# LargeDummyDevice register map
File version: 1.0
Registers are 32-bit, read-write, no defined reset value unless marked. A register's access mark holds for its fields unless they carry their own. Offsets are from the block's base; [hi:lo] are bit positions.

## PERIPHERAL_81
Base 0x40050000
0x04 REG_1 — Register 1
  [33:30] FIELD_1, [24] FIELD_19, [26:22] FIELD_5, [25:21] FIELD_7, [24:21] FIELD_18, [18:17] FIELD_13, [19:17] FIELD_20, [16:15] FIELD_14, [15:14] FIELD_2, [15:14] FIELD_6, [18:14] FIELD_11, [15:13] FIELD_8, [15:12] FIELD_16, [12:10] FIELD_21, [12:9] FIELD_3, [11:9] FIELD_17, [10:9] FIELD_22, [9:6] FIELD_10, [8:5] FIELD_4, [2] FIELD_12, [4:2] FIELD_15, [3:1] FIELD_23, [2:0] FIELD_9
0x08 REG_2 — Register 2
  [32:30] FIELD_4, [34:30] FIELD_6, [32:28] FIELD_11, [23] FIELD_3, [26:22] FIELD_20, [21] FIELD_1, [19] FIELD_21, [19:16] FIELD_2, [19:15] FIELD_7, [19:15] FIELD_19, [18:14] FIELD_24, [11:10] FIELD_9, [10:8] FIELD_16, [12:8] FIELD_17, [12:8] FIELD_18, [7] FIELD_22, [6] FIELD_8, [8:5] FIELD_15, [6:4] FIELD_5, [5:3] FIELD_13, [5:1] FIELD_12, [2:1] FIELD_23, [0] FIELD_10, [1:0] FIELD_14
0x0C REG_3 — Register 3
  [32:28] FIELD_1, [28] FIELD_5, [29:26] FIELD_4, [26:23] FIELD_7, [24:20] FIELD_9, [15:14] FIELD_14, [11:10] FIELD_11, [11:10] FIELD_12, [8:7] FIELD_6, [5] FIELD_2, [6:5] FIELD_8, [8:4] FIELD_10, [2] FIELD_3, [4:2] FIELD_13
0x10 REG_4 — Register 4
  [33:31] FIELD_3, [31:29] FIELD_1, [29:28] FIELD_4, [29:28] FIELD_9, [32:28] FIELD_11, [25:23] FIELD_2, [24:23] FIELD_15, [20] FIELD_5, [22:18] FIELD_10, [20:18] FIELD_13, [19:15] FIELD_7, [16:14] FIELD_6, [14:13] FIELD_8, [5:4] FIELD_12, [6:3] FIELD_14
0x14 REG_5 — Register 5
  [31:27] FIELD_1, [29:25] FIELD_5, [23] FIELD_6, [22:19] FIELD_9, [19:18] FIELD_7, [16:15] FIELD_4, [17:13] FIELD_3, [12] FIELD_8, [4:0] FIELD_2
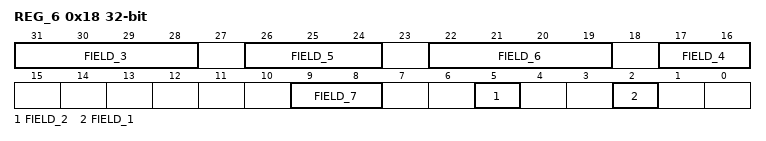
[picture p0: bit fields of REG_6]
0x18 REG_6 — Register 6
  [31:28] FIELD_3, [26:24] FIELD_5, [22:19] FIELD_6, [17:16] FIELD_4, [9:8] FIELD_7, [5] FIELD_2, [2] FIELD_1
0x1C REG_7 — Register 7
  [31] FIELD_18, [30:29] FIELD_20, [30:28] FIELD_11, [28:27] FIELD_13, [27:25] FIELD_22, [20:19] FIELD_15, [20:18] FIELD_1, [20:16] FIELD_16, [18:15] FIELD_7, [17:15] FIELD_17, [13] FIELD_9, [12:11] FIELD_2, [14:10] FIELD_10, [9:8] FIELD_21, [8:6] FIELD_12, [5] FIELD_19, [7:4] FIELD_8, [7:3] FIELD_4, [3] FIELD_6, [1] FIELD_3, [4:1] FIELD_14, [0] FIELD_5
0x20 REG_8 — Register 8
  [30] FIELD_14, [29] FIELD_4, [31:29] FIELD_12, [27] FIELD_11, [27:26] FIELD_13, [28:25] FIELD_1, [27:25] FIELD_21, [28:24] FIELD_15, [18:17] FIELD_20, [15:14] FIELD_3, [11] FIELD_2, [12:11] FIELD_5, [11] FIELD_8, [14:11] FIELD_17, [14:10] FIELD_19, [8] FIELD_6, [8:6] FIELD_7, [5] FIELD_18, [4] FIELD_10, [4:2] FIELD_16, [5:1] FIELD_9
0x24 REG_9 — Register 9
  [32:31] FIELD_2, [32:28] FIELD_4, [28:25] FIELD_3, [29:25] FIELD_7, [22:18] FIELD_6, [12:8] FIELD_1, [10:8] FIELD_5, [9:6] FIELD_8
0x28 REG_10 — Register 10
  [33:31] FIELD_1, [28:27] FIELD_4, [22:20] FIELD_2, [7:5] FIELD_3
0x2C REG_11 — Register 11
  [23] FIELD_2, [25:21] FIELD_7, [19:18] FIELD_3, [21:18] FIELD_6, [20:16] FIELD_8, [18:14] FIELD_12, [13] FIELD_4, [15:11] FIELD_10, [13:10] FIELD_5, [13:9] FIELD_9, [8:4] FIELD_13, [7:3] FIELD_1, [6:3] FIELD_11
0x30 REG_12 — Register 12
  [34:31] FIELD_26, [34:30] FIELD_17, [29] FIELD_7, [33:29] FIELD_8, [32:29] FIELD_27, [29] FIELD_29, [32:28] FIELD_25, [27:26] FIELD_13, [25:24] FIELD_1, [25:22] FIELD_10, [22:21] FIELD_20, [20] FIELD_19, [20:19] FIELD_23, [21:19] FIELD_28, [18:17] FIELD_3, [19:16] FIELD_6, [16] FIELD_16, [16] FIELD_21, [20:16] FIELD_22, [16:14] FIELD_12, [17:13] FIELD_9, [14:12] FIELD_2, [12] FIELD_14, [13:10] FIELD_4, [14:10] FIELD_24, [12:8] FIELD_11, [9:8] FIELD_30, [8:7] FIELD_5, [9:7] FIELD_15, [3:1] FIELD_18
0x34 REG_13 — Register 13
  [35:31] FIELD_15, [29:28] FIELD_2, [30:28] FIELD_5, [30:28] FIELD_16, [28:25] FIELD_25, [26:22] FIELD_24, [22:19] FIELD_8, [15] FIELD_1, [19:15] FIELD_6, [15:14] FIELD_3, [15:14] FIELD_12, [18:14] FIELD_18, [15:14] FIELD_21, [13:9] FIELD_17, [12:9] FIELD_20, [8:7] FIELD_9, [10:7] FIELD_13, [9:6] FIELD_10, [10:6] FIELD_14, [5] FIELD_4, [7:5] FIELD_19, [8:5] FIELD_22, [3:1] FIELD_11, [2:1] FIELD_23, [2:1] FIELD_26, [4:0] FIELD_7
0x38 REG_14 — Register 14
  [30:29] FIELD_1, [27:23] FIELD_3, [23] FIELD_5, [26:22] FIELD_2, [24:20] FIELD_7, [22:18] FIELD_6, [18:15] FIELD_10, [18:14] FIELD_8, [15:13] FIELD_9, [15:13] FIELD_12, [6] FIELD_11, [8:4] FIELD_4
0x3C REG_15 — Register 15
  [29] FIELD_2, [30:29] FIELD_7, [29] FIELD_20, [33:29] FIELD_27, [28] FIELD_21, [30:26] FIELD_9, [25] FIELD_24, [27:24] FIELD_28, [22] FIELD_16, [26:22] FIELD_22, [24:21] FIELD_25, [20:19] FIELD_26, [22:18] FIELD_18, [17:16] FIELD_11, [9] FIELD_15, [10:9] FIELD_17, [10:8] FIELD_5, [8] FIELD_13, [10:7] FIELD_4, [8:7] FIELD_8, [11:7] FIELD_10, [8:7] FIELD_12, [9:6] FIELD_19, [8:4] FIELD_1, [1] FIELD_6, [4:0] FIELD_3, [0] FIELD_14, [2:0] FIELD_23
0x40 REG_16 — Register 16
  [32:31] FIELD_7, [31:30] FIELD_11, [30:29] FIELD_4, [30:26] FIELD_14, [22] FIELD_5, [21:19] FIELD_12, [19] FIELD_15, [18:16] FIELD_20, [18:15] FIELD_3, [16:14] FIELD_10, [14] FIELD_23, [16:12] FIELD_21, [14:11] FIELD_19, [14:10] FIELD_13, [11:8] FIELD_17, [8:5] FIELD_6, [8:4] FIELD_16, [3] FIELD_9, [5:2] FIELD_18, [6:2] FIELD_22, [5:1] FIELD_1, [1:0] FIELD_2, [4:0] FIELD_8
0x44 REG_17 — Register 17
  [16] FIELD_5, [17:14] FIELD_2, [17:14] FIELD_4, [14:10] FIELD_1, [11:7] FIELD_3
0x48 REG_18 — Register 18
  [32:30] FIELD_14, [28] FIELD_28, [31:27] FIELD_21, [24] FIELD_18, [23] FIELD_6, [22:21] FIELD_5, [23:21] FIELD_26, [22:20] FIELD_17, [22:19] FIELD_22, [22:18] FIELD_20, [22:18] FIELD_23, [18:16] FIELD_15, [16:13] FIELD_1, [10:9] FIELD_19, [10:6] FIELD_3, [7:6] FIELD_7, [8:6] FIELD_9, [5:4] FIELD_16, [5:3] FIELD_4, [6:3] FIELD_8, [3] FIELD_11, [2] FIELD_10, [4:2] FIELD_13, [5:2] FIELD_25, [3:1] FIELD_12, [5:1] FIELD_24, [0] FIELD_2, [0] FIELD_27
0x4C REG_19 — Register 19
  [29:28] FIELD_11, [31:27] FIELD_4, [22:21] FIELD_9, [22:19] FIELD_10, [18:16] FIELD_1, [19:16] FIELD_7, [14:12] FIELD_5, [12:11] FIELD_12, [10:9] FIELD_13, [9:5] FIELD_14, [3] FIELD_2, [2] FIELD_3, [3:1] FIELD_6, [3:1] FIELD_8
0x50 REG_20 — Register 20
  [30:29] FIELD_1, [31:29] FIELD_15, [26:25] FIELD_2, [26:23] FIELD_3, [26:23] FIELD_10, [21:17] FIELD_8, [20:17] FIELD_9, [20:17] FIELD_14, [15] FIELD_7, [16:13] FIELD_16, [15:12] FIELD_13, [12:9] FIELD_6, [9:8] FIELD_12, [5] FIELD_5, [6:3] FIELD_4, [6:3] FIELD_11
0x54 REG_21 — Register 21
  [32:31] FIELD_10, [30:28] FIELD_8, [27:26] FIELD_4, [25:24] FIELD_2, [27:24] FIELD_3, [25:23] FIELD_7, [21:20] FIELD_9, [20:19] FIELD_5, [12:8] FIELD_6, [5:3] FIELD_1
0x58 REG_22 — Register 22
  [26:23] FIELD_3, [24:22] FIELD_5, [23:19] FIELD_2, [19:18] FIELD_8, [17:13] FIELD_7, [11] FIELD_6, [8] FIELD_4, [5:1] FIELD_1
0x5C REG_23 — Register 23
  [33:30] FIELD_14, [30] FIELD_15, [29] FIELD_6, [29] FIELD_8, [30:28] FIELD_5, [31:28] FIELD_13, [26:23] FIELD_9, [26:22] FIELD_3, [24:21] FIELD_17, [22:20] FIELD_4, [13] FIELD_10, [11:8] FIELD_7, [11:7] FIELD_11, [9:5] FIELD_16, [7:3] FIELD_2, [3:2] FIELD_1, [3:1] FIELD_12
0x60 REG_24 — Register 24
  [31] FIELD_3, [30] FIELD_2, [28] FIELD_6, [26:25] FIELD_7, [22:19] FIELD_5, [16:15] FIELD_1, [12] FIELD_9, [13:11] FIELD_8, [8] FIELD_4
0x64 REG_25 — Register 25
  [35:31] FIELD_5, [32:29] FIELD_8, [25:23] FIELD_6, [25:21] FIELD_9, [17] FIELD_2, [11] FIELD_3, [11:8] FIELD_7, [9:7] FIELD_4, [6:5] FIELD_1, [7:5] FIELD_11, [6:5] FIELD_12, [4:1] FIELD_10, [2:0] FIELD_13
0x68 REG_26 — Register 26
  [25] FIELD_3, [17] FIELD_4, [17:16] FIELD_1, [9] FIELD_2
